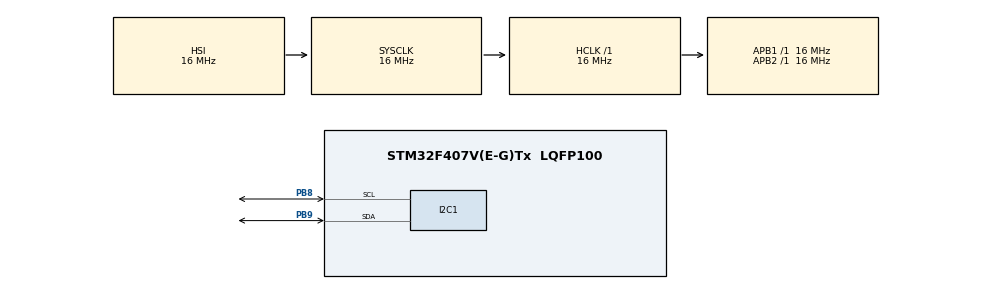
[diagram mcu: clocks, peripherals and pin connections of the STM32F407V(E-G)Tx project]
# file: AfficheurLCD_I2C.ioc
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Mcu.Family=STM32F4
Mcu.Name=STM32F407V(E-G)Tx
Mcu.Package=LQFP100
NVIC.PriorityGroup=NVIC_PRIORITYGROUP_4
PB8.Mode=I2C
PB8.Signal=I2C1_SCL
PB9.Mode=I2C
PB9.Signal=I2C1_SDA
ProjectManager.HeapSize=0x200
ProjectManager.StackSize=0x400
ProjectManager.TargetToolchain=STM32CubeIDE
RCC.AHBFreq_Value=16000000
RCC.APB1Freq_Value=16000000
RCC.APB2Freq_Value=16000000
RCC.CortexFreq_Value=16000000
RCC.HSE_VALUE=25000000
RCC.HSI_VALUE=16000000
RCC.LSE_VALUE=32768
RCC.SYSCLKFreq_VALUE=16000000
RCC.VCOOutputFreq_Value=192000000
board=custom

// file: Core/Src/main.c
/* USER CODE BEGIN Header */
/**
  ******************************************************************************
  * @file           : main.c
  * @brief          : Main program body
  ******************************************************************************
  * @attention
  *
  * Copyright (c) 2024 STMicroelectronics.
  * All rights reserved.
  *
  * This software is licensed under terms that can be found in the LICENSE file
  * in the root directory of this software component.
  * If no LICENSE file comes with this software, it is provided AS-IS.
  *
  ******************************************************************************
  */
/* USER CODE END Header */
#include "main.h"

/* USER CODE BEGIN Includes */
#include "liquidcrystal_i2c.h"
/* USER CODE END Includes */

I2C_HandleTypeDef hi2c1;

/* USER CODE BEGIN PV */
uint8_t Heart[8] = {
    0b00000,
    0b01010,
    0b11111,
    0b11111,
    0b01110,
    0b00100,
    0b00000,
    0b00000
};

uint8_t yass[8] = {
    0b11111,
    0b10001,
	0b10001,
	0b10001,
	0b10001,
	0b10001,
	0b10001,
    0b11111
};
/* USER CODE END PV */

void SystemClock_Config(void);
static void MX_GPIO_Init(void);
static void MX_I2C1_Init(void);

int main(void)
{

  /* MCU Configuration--------------------------------------------------------*/

  /* Reset of all peripherals, Initializes the Flash interface and the Systick. */
  HAL_Init();

  /* Configure the system clock */
  SystemClock_Config();

  /* Initialize all configured peripherals */
  MX_GPIO_Init();
  MX_I2C1_Init();
  /* USER CODE BEGIN 2 */

    HD44780_Init(2);
    HD44780_SetCursor(0,0);
    HD44780_PrintStr("Hello STM32");
    HAL_Delay(1000);
    HD44780_Clear();
    HD44780_SetCursor(0,0);
    HD44780_PrintStr("this is the first Project with LCD");

      for(int x=0; x<40; x=x+1)
      {
        HD44780_ScrollDisplayLeft();  //HD44780_ScrollDisplayRight();
        HAL_Delay(500);
      }

     HD44780_Clear();
     HD44780_SetCursor(0,0);
     HD44780_Blink();
     HAL_Delay(1000);
     HD44780_PrintStr("y");
     HAL_Delay(400);
     HD44780_SetCursor(1,0);
     HD44780_PrintStr("a");
     HAL_Delay(400);
     HD44780_SetCursor(2,0);
     HD44780_PrintStr("s");
     HAL_Delay(400);
     HD44780_SetCursor(3,0);
     HD44780_PrintStr("s");
     HAL_Delay(400);
     HD44780_SetCursor(4,0);
     HD44780_PrintStr("i");
     HAL_Delay(400);
     HD44780_SetCursor(5,0);
     HD44780_PrintStr("n");
     HAL_Delay(400);
     HD44780_SetCursor(6,0);
     HD44780_PrintStr("e");
     HAL_Delay(1000);

     HD44780_Clear();
     HAL_Delay(400);
     HD44780_SetCursor(0,0);
     HD44780_PrintStr("yassine");

     HD44780_Clear();
     // Création du caractère spécial (le cœur) à l'adresse 0 de la mémoire LCD
     HD44780_CreateSpecialChar(0, Heart);  // Enregistrer le cœur dans la mémoire de l'écran

     // Affichage du cœur
     HD44780_SetCursor(1, 0);  // Déplacer le curseur à la ligne 1
     HD44780_PrintSpecialChar(0);  // Afficher le cœur (caractère spécial à l'adresse 0)

     HD44780_CreateSpecialChar(1,yass);
     HD44780_SetCursor(4, 0);
     HD44780_PrintSpecialChar(1);

    /*
    char snum[5];
    for ( int x = 1; x <= 10 ; x++ )
    {
      itoa(x, snum, 10);
      HD44780_Clear();
      HD44780_SetCursor(0,0);
      HD44780_PrintStr(snum);
      HAL_Delay (1000);
    }*/
    /* USER CODE END 2 */

  /* Infinite loop */
  while (1)
  {

  }
}

void SystemClock_Config(void)
{
  RCC_OscInitTypeDef RCC_OscInitStruct = {0};
  RCC_ClkInitTypeDef RCC_ClkInitStruct = {0};

  /** Configure the main internal regulator output voltage
  */
  __HAL_RCC_PWR_CLK_ENABLE();
  __HAL_PWR_VOLTAGESCALING_CONFIG(PWR_REGULATOR_VOLTAGE_SCALE1);

  /** Initializes the RCC Oscillators according to the specified parameters
  * in the RCC_OscInitTypeDef structure.
  */
  RCC_OscInitStruct.OscillatorType = RCC_OSCILLATORTYPE_HSI;
  RCC_OscInitStruct.HSIState = RCC_HSI_ON;
  RCC_OscInitStruct.HSICalibrationValue = RCC_HSICALIBRATION_DEFAULT;
  RCC_OscInitStruct.PLL.PLLState = RCC_PLL_NONE;
  if (HAL_RCC_OscConfig(&RCC_OscInitStruct) != HAL_OK)
  {
    Error_Handler();
  }

  /** Initializes the CPU, AHB and APB buses clocks
  */
  RCC_ClkInitStruct.ClockType = RCC_CLOCKTYPE_HCLK|RCC_CLOCKTYPE_SYSCLK
                              |RCC_CLOCKTYPE_PCLK1|RCC_CLOCKTYPE_PCLK2;
  RCC_ClkInitStruct.SYSCLKSource = RCC_SYSCLKSOURCE_HSI;
  RCC_ClkInitStruct.AHBCLKDivider = RCC_SYSCLK_DIV1;
  RCC_ClkInitStruct.APB1CLKDivider = RCC_HCLK_DIV1;
  RCC_ClkInitStruct.APB2CLKDivider = RCC_HCLK_DIV1;

  if (HAL_RCC_ClockConfig(&RCC_ClkInitStruct, FLASH_LATENCY_0) != HAL_OK)
  {
    Error_Handler();
  }
}

static void MX_I2C1_Init(void)
{

  hi2c1.Instance = I2C1;
  hi2c1.Init.ClockSpeed = 100000;
  hi2c1.Init.DutyCycle = I2C_DUTYCYCLE_2;
  hi2c1.Init.OwnAddress1 = 0;
  hi2c1.Init.AddressingMode = I2C_ADDRESSINGMODE_7BIT;
  hi2c1.Init.DualAddressMode = I2C_DUALADDRESS_DISABLE;
  hi2c1.Init.OwnAddress2 = 0;
  hi2c1.Init.GeneralCallMode = I2C_GENERALCALL_DISABLE;
  hi2c1.Init.NoStretchMode = I2C_NOSTRETCH_DISABLE;
  if (HAL_I2C_Init(&hi2c1) != HAL_OK)
  {
    Error_Handler();
  }

}

static void MX_GPIO_Init(void)
{

  /* GPIO Ports Clock Enable */
  __HAL_RCC_GPIOB_CLK_ENABLE();

}

void Error_Handler(void)
{
  __disable_irq();
  while (1)
  {
  }
}
